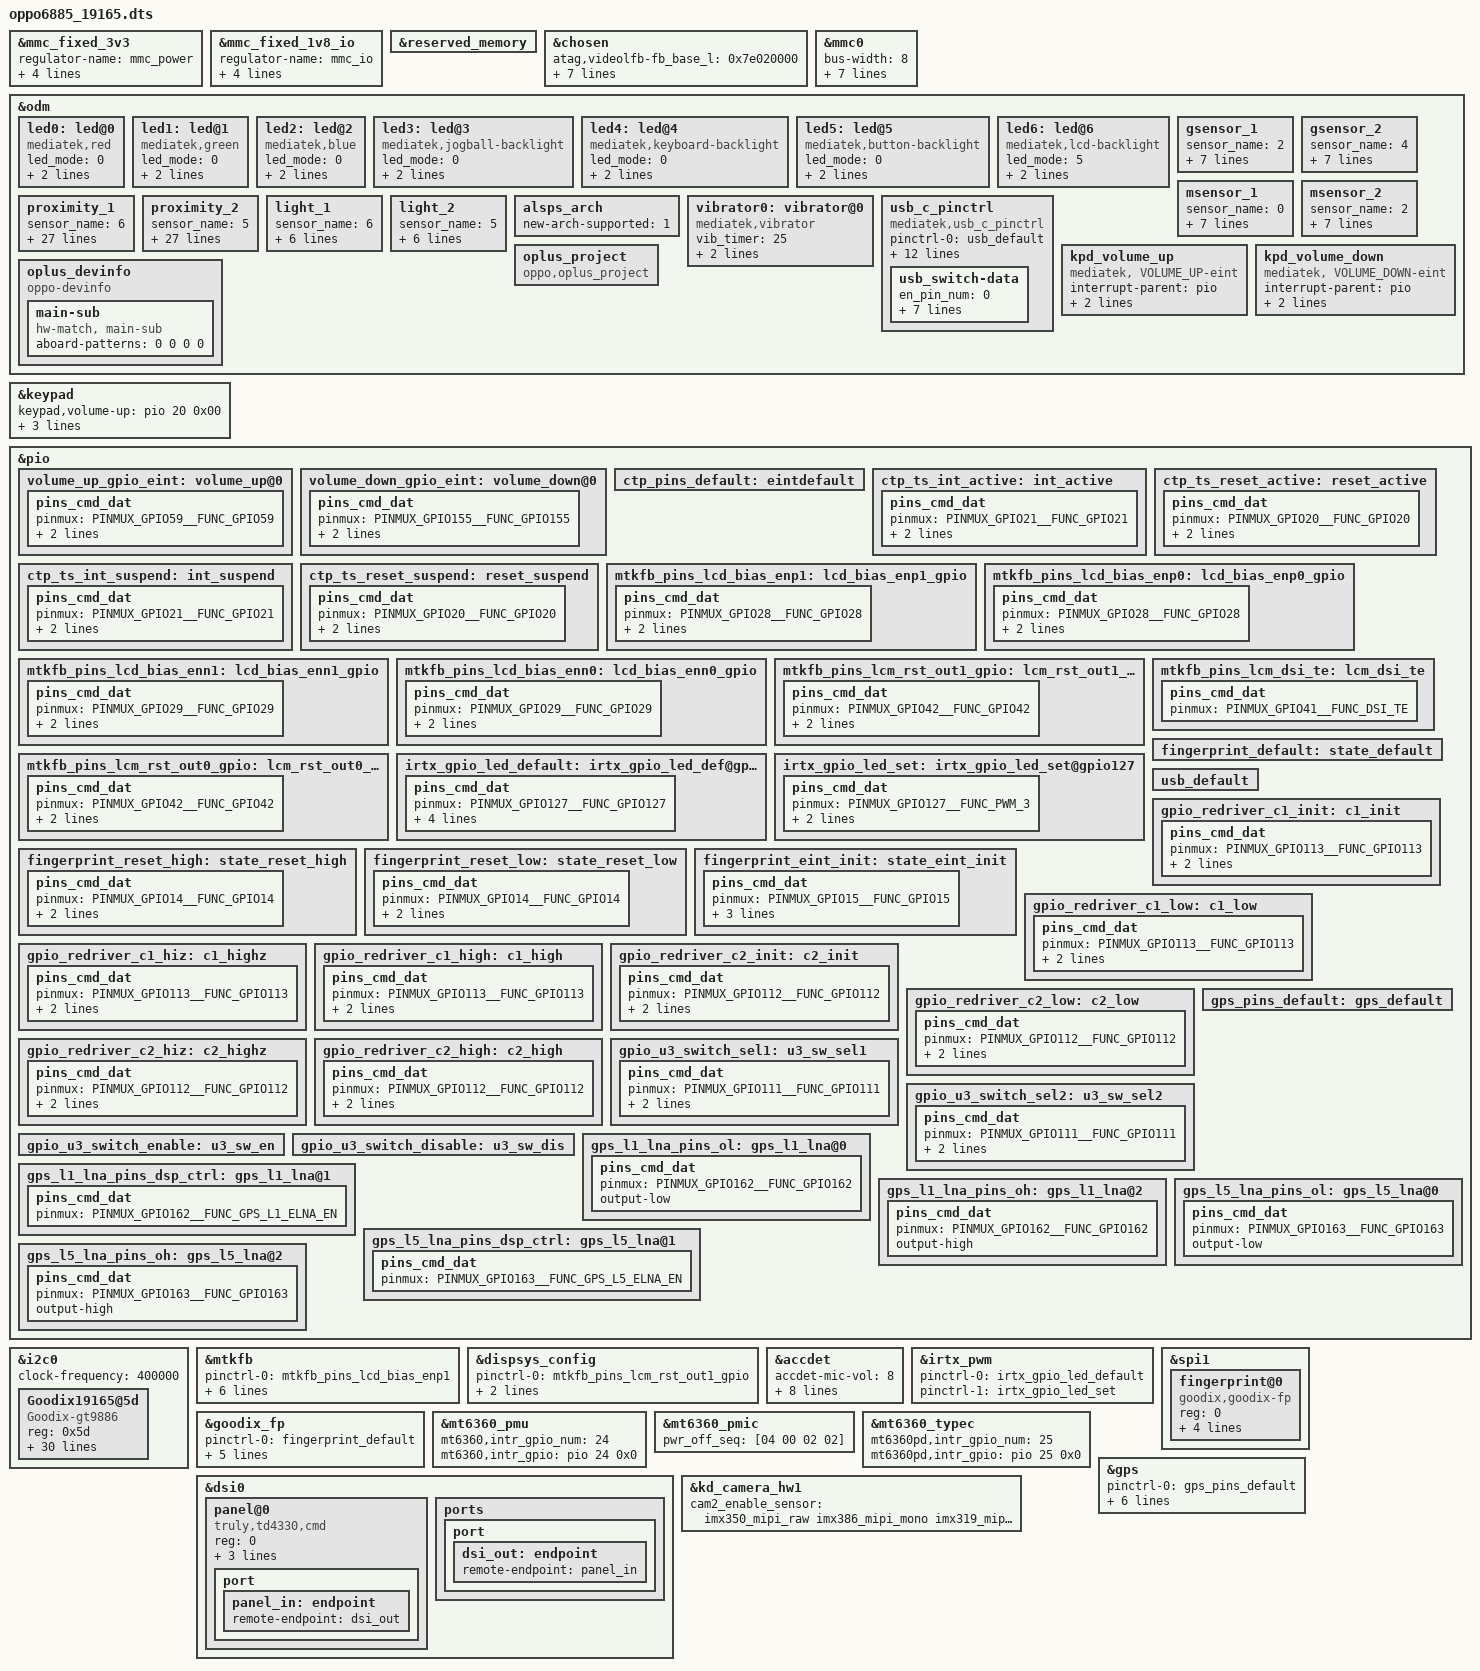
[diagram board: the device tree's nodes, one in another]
/*
 * Mediatek's mt6885 SoC device tree source
 *
 * Copyright (C) 2016 MediaTek Inc.
 *
 * This program is free software; you can redistribute it and/or modify
 * it under the terms of the GNU General Public License version 2 as
 * published by the Free Software Foundation.
 *
 * This program is distributed in the hope that it will be useful,
 * but WITHOUT ANY WARRANTY; without even the implied warranty of
 * MERCHANTABILITY or FITNESS FOR A PARTICULAR PURPOSE.
 * See http://www.gnu.org/licenses/gpl-2.0.html for more details.
 */
/dts-v1/;
/plugin/;
#include <dt-bindings/interrupt-controller/irq.h>
#include <dt-bindings/interrupt-controller/arm-gic.h>
#include <dt-bindings/spmi/spmi.h>
#include <dt-bindings/pinctrl/mt6885-pinfunc.h>

&mmc_fixed_3v3 {
	status = "okay";
	regulator-name = "mmc_power";
	regulator-min-microvolt = <3300000>;
	regulator-max-microvolt = <3300000>;
	enable-active-high;
	regulator-always-on;
};

&mmc_fixed_1v8_io {
	status = "okay";
	regulator-name = "mmc_io";
	regulator-min-microvolt = <1800000>;
	regulator-max-microvolt = <1800000>;
	enable-active-high;
	regulator-always-on;
};

&reserved_memory {
};

/* chosen */
&chosen {

	atag,videolfb-fb_base_l = <0x7e020000>;
	atag,videolfb-fb_base_h = <0x0>;
	atag,videolfb-islcmfound = <1>;
	atag,videolfb-islcm_inited = <0>;
	atag,videolfb-fps= <6000>;
	atag,videolfb-vramSize= <0x1be0000>;
	atag,videolfb-lcmname=
		"nt35595_fhd_dsi_cmd_truly_nt50358_drv";
};

&mmc0 {
	status = "okay";
	/* pinctrl-names = "default", "state_uhs"; */
	/* pinctrl-0 = <&mmc0_pins_default>; */
	/* pinctrl-1 = <&mmc0_pins_uhs>; */
	bus-width = <8>;
	max-frequency = <5000000>;
	cap-mmc-highspeed;
	no-sdio;
	no-sd;
	vmmc-supply = <&mmc_fixed_3v3>;
	vqmmc-supply = <&mmc_fixed_1v8_io>;
	non-removable;
};

&odm {
	led0:led@0 {
		compatible = "mediatek,red";
		led_mode = <0>;
		data = <1>;
		pwm_config = <0 0 0 0 0>;
	};
	led1:led@1 {
		compatible = "mediatek,green";
		led_mode = <0>;
		data = <1>;
		pwm_config = <0 0 0 0 0>;
	};
	led2:led@2 {
		compatible = "mediatek,blue";
		led_mode = <0>;
		data = <1>;
		pwm_config = <0 0 0 0 0>;
	};
	led3:led@3 {
		compatible = "mediatek,jogball-backlight";
		led_mode = <0>;
		data = <1>;
		pwm_config = <0 0 0 0 0>;
	};
	led4:led@4 {
		compatible = "mediatek,keyboard-backlight";
		led_mode = <0>;
		data = <1>;
		pwm_config = <0 0 0 0 0>;
	};
	led5:led@5 {
		compatible = "mediatek,button-backlight";
		led_mode = <0>;
		data = <1>;
		pwm_config = <0 0 0 0 0>;
	};
	led6:led@6 {
		compatible = "mediatek,lcd-backlight";
		led_mode = <5>;
		data = <1>;
		pwm_config = <0 1 0 0 0>;
	};
	/*
	enum {
		LIS3DH,
		LSM6DS3,
		BMI160,
		LIS2HH12,
		LSM6DSM,
		BMI2XY,
	};
	*/
	gsensor_1: gsensor_1 {
		status = "okay";
		sensor_name = <2>;//BMI160
		i2c_num = <2>;
		i2c_addr = <0>;
		direction = <7>;
		eint_num = <3>;
		step_count_7_en = <1>;
		config_miso = <1>;
		correct_y_bias = <1>;
	};

	gsensor_2: gsensor_2 {
		status = "okay";
		sensor_name = <4>;//LSM6DSM
		i2c_num = <2>;
		i2c_addr = <0>;
		direction = <5>;
		eint_num = <3>;
		step_count_7_en = <1>;
		config_miso = <1>;
		correct_y_bias = <1>;
	};
	/*
	enum {
		AKM09911,
		MMC3530,
		MMC5603,
		MXG4300,
	};
	*/
	msensor_1: msensor_1 {
		status = "okay";
		sensor_name = <0>;//AKM09911
		i2c_num = <0>;
		i2c_addr = <12>;
		direction = <4>;
		eint_num = <0>;
		parameter-number= <18>;
		soft-mag-parameter = <9263 1 322 0 140 0 48 1 10701 1 125 0 103 1 140 1 10726 1>; // not using
	};
	msensor_2: msensor_2 {
		status = "okay";
		sensor_name = <2>;//MMC5603
		i2c_num = <0>;
		i2c_addr = <48>;
		direction = <7>;
		eint_num = <0>;
		parameter-number= <18>;
		soft-mag-parameter = <9991 0 412 0 85 1 122 1 10184 0 328 1 186 1 14 0 10516 0>;
	};
	/*
	enum {
		TMD2725,
		APSD9922,
		STK3335,
		STK3331,
		STK2232,
		TCS3701,
		STK32600,
	};
	*/
	proximity_1: proximity_1 {
		status = "okay";
		sensor_name = <6>;//STK32600
		i2c_num = <0>;
		i2c_addr = <72>;
		direction = <4>;
		eint_num = <11>;
		low_step = <300>;
		high_step = <400>;
		low_limit = <650>;
		high_limit = <1050>;
		dirty_low_step = <300>;
		dirty_high_step = <400>;
		ps_dirty_limit = <1800>;
		ps_ir_limit = <2000>;
		ps_adjust_min = <0>;
		ps_adjust_max = <1850>;
		sampling_count = <5>;
		step_max = <400>;
		step_min = <100>;
		step_div = <2000>;
		anti_shake_delta = <70>;
		dynamic_cali_max = <2000>;
		raw2offset_radio = <1000>;
		offset_max = <60000>;
		offset_range_min = <0>;
		offset_range_max = <65534>;
		force_cali_limit = <2000>;
		cali_jitter_limit = <20>;
		cal_offset_margin = <3000>;
	};
	proximity_2: proximity_2 {
		status = "okay";
		sensor_name = <5>;//TCS3701
		i2c_num = <0>;
		i2c_addr = <57>;
		direction = <4>;
		eint_num = <11>;
		low_step = <300>;
		high_step = <400>;
		low_limit = <400>;
		high_limit = <600>;
		dirty_low_step = <180>;
		dirty_high_step = <250>;
		ps_dirty_limit = <1023>;
		ps_ir_limit = <500>;
		ps_adjust_min = <0>;
		ps_adjust_max = <600>;
		sampling_count = <5>;
		step_max = <400>;
		step_min = <110>;
		step_div = <1500>;
		anti_shake_delta = <80>;
		dynamic_cali_max = <1024>;
		raw2offset_radio = <20800>;
		offset_max = <250>;
		offset_range_min = <255>;
		offset_range_max = <255>;
		force_cali_limit = <2000>;
		cali_jitter_limit = <30>;
		cal_offset_margin = <120>;
	};
	light_1: light_1 {
		status = "okay";
		sensor_name = <6>;//STK32600
		i2c_num = <0>;
		i2c_addr = <72>;
		direction = <4>;
		eint_num = <11>;
		als_buffer_length =<8>;
		als_ratio = <65>;
	};
	light_2: light_2 {
		status = "okay";
		sensor_name = <5>;//TCS3701
		i2c_num = <0>;
		i2c_addr = <57>;
		direction = <4>;
		eint_num = <11>;
		als_buffer_length = <10>;
		als_ratio = <110>;
	};
	alsps_arch: alsps_arch {
		status = "okay";
		new-arch-supported = <1>;
	};
	vibrator0:vibrator@0 {
		compatible = "mediatek,vibrator";
		vib_timer = <25>;
		vib_limit = <9>;
		vib_vol= <9>;
	};
	usb_c_pinctrl:usb_c_pinctrl {
		compatible = "mediatek,usb_c_pinctrl";
	};

/*VENDOR_EDIT keypad start*/
	kpd_volume_up:kpd_volume_up {
		compatible = "mediatek, VOLUME_UP-eint";
		interrupt-parent = <&pio>;
		interrupts = <59 IRQ_TYPE_EDGE_FALLING 59 0>;
		debounce = <32000>;
		status = "okay";
	};

	kpd_volume_down:kpd_volume_down {
		compatible = "mediatek, VOLUME_DOWN-eint";
		interrupt-parent = <&pio>;
		interrupts = <155 IRQ_TYPE_EDGE_FALLING 155 0>;
		debounce = <32000>;
		status = "okay";
	};
/*VENDOR_EDIT keypad end*/

	oplus_project:oplus_project {
		compatible = "oppo,oplus_project";
	};
	oplus_devinfo:oplus_devinfo {
		compatible = "oppo-devinfo";

		main-sub {
			compatible = "hw-match, main-sub";
			aboard-patterns = <0 0 0 0>;
			/*main board*/
			//match-projects = <19537 19538 19541 19539>;
		};
	};
};
/*VENDOR_EDIT*/
&keypad {
	keypad,volume-up	= <&pio 20 0x00>;
	keypad,volume-down	= <&pio 155 0x00>;
	pinctrl-names = "volume_up_as_int", "volume_down_as_int";
	pinctrl-0 = <&volume_up_gpio_eint>;
	pinctrl-1 = <&volume_down_gpio_eint>;
	status = "okay";
};

&pio {
	volume_up_gpio_eint:volume_up@0{
		pins_cmd_dat {
			pinmux = <PINMUX_GPIO59__FUNC_GPIO59>;
			slew-rate = <0>;  /*direction 0:in, 1:out*/
			input-enable;
		};
	};

	volume_down_gpio_eint:volume_down@0{
		pins_cmd_dat {
			pinmux = <PINMUX_GPIO155__FUNC_GPIO155>;
			slew-rate = <0>;  /*direction 0:in, 1:out*/
			input-enable;
		};
	};
};
/*VENDOR_EDIT*/
&i2c0 {
	clock-frequency = <400000>;
	status = "okay";
	Goodix19165@5d {
		compatible = "Goodix-gt9886";
		reg = <0x5d>;
		chip-name = "GT9886";

		/* Interrupt && Irq-gpio */
		interrupt-parent = <&pio>;
		interrupts = <21 IRQ_TYPE_EDGE_FALLING 21 0>;

		/* Power Config */
		vdd_2v8-supply = <&mt_pmic_vtp_ldo_reg>;
		vdd_2v8_volt = <2950000>;

		/* Other HW Resource */
		irq-gpio = <&pio 21 0x2002>;
		reset-gpio = <&pio 20 0>;
		pinctrl-names = "default";

		vid_len = <0>;
		tp_type = <8>;
		// type of tp_dev ,TP-SAMSUNG = 8;
		platform_support_project = <19165 19166>;
		platform_support_project_dir = <19165 19165>;
		platform_support_project_commandline = "s68fc01", "s68fc01";

		touchpanel,max-num-support = <10>;
		touchpanel,tx-rx-num = <15 34>;
		touchpanel,panel-coords = <1080 2400>;
		touchpanel,display-coords = <1080 2400>;
		touchpanel,touchmajor-limit = <0 54>;

		/* SW Support Feature Control */
		register-is-16bit;
		black_gesture_support;
		fw_edge_limit_support;
		pressure_report_support;
		//spurious_fingerprint_support;
		charger_pump_support;
		game_switch_support;
		//face_detect_support;
		smart_gesture_support;
		fw_update_app_support;
		fingerprint_underscreen_support;
		esd_handle_support;
		/*
		 *Virtual Key Config:
		 *1:touchpanel,button-type: <virtualkey_type  supportted_button-map>
		 *virtualkey_type:
		 *Type 1: using board_properties
		 *Type 2: using same IC (button zone&& touch zone are seprate)
		 *Type 3: using diffrent IC (button zone&& touch zone are seprate)
		 *Type 4: No need of virtual key process
		 *supportted_button-map:select|menu|home|back
		 *
		 *2:touchpanel,button-map
		 *type (X1,Y1)(X2,Y2)(X3,Y3)(Width_X,Hight_Y)--Only when button-type is 0
		 */
		touchpanel,button-type = <4>;
		touchpanel.button-TRx = <0 0>;
	};

};
&pio {
	ctp_pins_default: eintdefault {
	};
	ctp_ts_int_active: int_active {
		pins_cmd_dat {
			pinmux = <PINMUX_GPIO21__FUNC_GPIO21>;
			slew-rate = <0>;
			bias-pull-up = <11>;
		};
	};
	ctp_ts_reset_active: reset_active {
		pins_cmd_dat {
			pinmux = <PINMUX_GPIO20__FUNC_GPIO20>;
			slew-rate = <1>;
			output-high;
		};
	};
	ctp_ts_int_suspend: int_suspend {
		pins_cmd_dat {
			pinmux = <PINMUX_GPIO21__FUNC_GPIO21>;
			slew-rate = <1>;
			output-low;
		};
	};
	ctp_ts_reset_suspend: reset_suspend {
		pins_cmd_dat {
			pinmux = <PINMUX_GPIO20__FUNC_GPIO20>;
			slew-rate = <1>;
			output-low;
		};
	};
};
/* TOUCH end */

/* DISPSYS GPIO standardization */
&pio {
	mtkfb_pins_lcd_bias_enp1: lcd_bias_enp1_gpio {
		pins_cmd_dat {
			pinmux = <PINMUX_GPIO28__FUNC_GPIO28>;
			slew-rate = <1>;
			output-high;
		};
	};

	mtkfb_pins_lcd_bias_enp0: lcd_bias_enp0_gpio {
		pins_cmd_dat {
			pinmux = <PINMUX_GPIO28__FUNC_GPIO28>;
			slew-rate = <1>;
			output-low;
		};
	};

	mtkfb_pins_lcd_bias_enn1: lcd_bias_enn1_gpio {
		pins_cmd_dat {
			pinmux = <PINMUX_GPIO29__FUNC_GPIO29>;
			slew-rate = <1>;
			output-high;
		};
	};

	mtkfb_pins_lcd_bias_enn0: lcd_bias_enn0_gpio {
		pins_cmd_dat {
			pinmux = <PINMUX_GPIO29__FUNC_GPIO29>;
			slew-rate = <1>;
			output-low;
		};
	};

	mtkfb_pins_lcm_rst_out1_gpio: lcm_rst_out1_gpio {
		pins_cmd_dat {
			pinmux = <PINMUX_GPIO42__FUNC_GPIO42>;
			slew-rate = <1>;
			output-high;
		};
	};

	mtkfb_pins_lcm_rst_out0_gpio: lcm_rst_out0_gpio {
		pins_cmd_dat {
			pinmux = <PINMUX_GPIO42__FUNC_GPIO42>;
			slew-rate = <1>;
			output-low;
		};
	};

	mtkfb_pins_lcm_dsi_te: lcm_dsi_te {
		pins_cmd_dat {
			pinmux = <PINMUX_GPIO41__FUNC_DSI_TE>;
		};
	};
};

&mtkfb {
	pinctrl-names = "lcd_bias_enp1_gpio", "lcd_bias_enp0_gpio",
		"lcd_bias_enn1_gpio", "lcd_bias_enn0_gpio",
		"lcm_rst_out1_gpio", "lcm_rst_out0_gpio",
		"mode_te_te";
	pinctrl-0 = <&mtkfb_pins_lcd_bias_enp1>;
	pinctrl-1 = <&mtkfb_pins_lcd_bias_enp0>;
	pinctrl-2 = <&mtkfb_pins_lcd_bias_enn1>;
	pinctrl-3 = <&mtkfb_pins_lcd_bias_enn0>;
	pinctrl-4 = <&mtkfb_pins_lcm_rst_out1_gpio>;
	pinctrl-5 = <&mtkfb_pins_lcm_rst_out0_gpio>;
	pinctrl-6 = <&mtkfb_pins_lcm_dsi_te>;
	status = "okay";
};

&dispsys_config {
	pinctrl-names =
		"lcm_rst_out1_gpio", "lcm_rst_out0_gpio",
		"mode_te_te";
	pinctrl-0 = <&mtkfb_pins_lcm_rst_out1_gpio>;
	pinctrl-1 = <&mtkfb_pins_lcm_rst_out0_gpio>;
	pinctrl-2 = <&mtkfb_pins_lcm_dsi_te>;
	status = "okay";
};
/* DISPSYS GPIO standardization end */

/* accdet start */
&accdet {
	/* accdet micbias voltage: 0x09:2.85v 0x08:2.8v 0x07,
	 * 2.7v;0x05,2.5v;0x02,1.9v
	 */
	accdet-mic-vol = <8>;
	/* accdet pwm_width, pwm_thresh, fall_delay, rise_delay
	 * debounce0, debounce1, debounce3, debounce4
	 * eint pwm_width, eint pwm_thresh
	 * eint deb(debounce0, debounce1, debounce2, debounce3), inv_debounce
	 */
	headset-mode-setting = <0x500 0x500 1 0x1f0
				0x800 0x800 0x20 0x44
				0x4 0x1
				0x5 0x3 0x3 0x5 0xe>;
	accdet-plugout-debounce = <1>;
	/*1:ACC mode, 2:low cost without in bias, 6:low cost with in bias*/
	accdet-mic-mode = <2>;
	/*0--MD_MAX--UP_MAX--DW_MAX*/
	headset-three-key-threshold = <0 80 220 400>;
	headset-three-key-threshold-CDD = <0 121 192 600>;
	/*0--MD_MAX--VOICE_MAX--UP_MAX--DW_MAX*/
	headset-four-key-threshold = <0 58 121 192 400>;

	/* select VTH to 2v and 500k, use internal resitance */
	eint_use_ext_res = <0>;
	status = "okay";
};
/* accdet end */

/* IRTX GPIO Start */
&irtx_pwm {
	pinctrl-names = "irtx_gpio_led_default", "irtx_gpio_led_set";
	pinctrl-0 = <&irtx_gpio_led_default>;
	pinctrl-1 = <&irtx_gpio_led_set>;
	status = "okay";
};
&pio {
	/* IRTX GPIO Settings -Start */
	/* default: GPIO0, output, high */
	irtx_gpio_led_default:irtx_gpio_led_def@gpio127 {
		pins_cmd_dat {
			pinmux = <PINMUX_GPIO127__FUNC_GPIO127>;
			slew-rate = <1>;
			bias-disable;
			output-low;
			input-schmitt-enable = <0>;
		};
	};

	irtx_gpio_led_set:irtx_gpio_led_set@gpio127 {
		pins_cmd_dat {
			pinmux = <PINMUX_GPIO127__FUNC_PWM_3>;
			slew-rate = <1>;
			output-high;
		};
	};
}; /* IRTX GPIO Settings -End */

/* FINGERPRINT start */
&spi1 {
	#address-cells = <1>;
	#size-cells = <0>;
	fingerprint@0 {
		compatible = "goodix,goodix-fp";
		reg = <0>;
		spi-max-frequency = <8000000>;
		netlink-event = <30>;
		vfp-supply = <&mt_pmic_vfp_ldo_reg>;
		power-type = <1>;
		status = "okay";
	};
};

&goodix_fp {
	pinctrl-names = "default", "reset_high", "reset_low", "eint_init";
	pinctrl-0 = <&fingerprint_default>;
	pinctrl-1 = <&fingerprint_reset_high>;
	pinctrl-2 = <&fingerprint_reset_low>;
	pinctrl-3 = <&fingerprint_eint_init>;
	interrupt-parent = <&pio>;
	interrupts = <15 IRQ_TYPE_EDGE_RISING 15 0>;
	status = "okay";
};

&pio {
	fingerprint_default: state_default {
	};
	fingerprint_reset_high: state_reset_high {
		pins_cmd_dat {
			pinmux = <PINMUX_GPIO14__FUNC_GPIO14>;
			slew-rate = <1>;
			output-high;
		};
	};
	fingerprint_reset_low: state_reset_low {
		pins_cmd_dat {
			pinmux = <PINMUX_GPIO14__FUNC_GPIO14>;
			slew-rate = <1>;
			output-low;
		};
	};
	fingerprint_eint_init: state_eint_init {
		pins_cmd_dat {
			pinmux = <PINMUX_GPIO15__FUNC_GPIO15>;
			slew-rate = <0>;
			bias-pull-up = <MTK_PUPD_SET_R1R0_10>;
			input-schmitt-enable;
		};
	};
};
/* FINGERPRINT end */

&mt6360_pmu {
	mt6360,intr_gpio_num = <24>; /* direct defined GPIO num */
	mt6360,intr_gpio = <&pio 24 0x0>;
};

&mt6360_pmic {
	pwr_off_seq = [04 00 02 02];
};

&mt6360_typec {
	mt6360pd,intr_gpio_num = <25>; /* direct defined GPIO num */
	mt6360pd,intr_gpio = <&pio 25 0x0>;
};

/* USB SWITCH GPIO start */
&pio {
	usb_default: usb_default {
	};

	gpio_redriver_c1_init: c1_init {
		pins_cmd_dat {
			pinmux = <PINMUX_GPIO113__FUNC_GPIO113>;
			slew-rate = <1>;
			output-low;
		};
	};

	gpio_redriver_c1_low: c1_low {
		pins_cmd_dat {
			pinmux = <PINMUX_GPIO113__FUNC_GPIO113>;
			slew-rate = <1>;
			output-low;
		};
	};

	gpio_redriver_c1_hiz: c1_highz {
		pins_cmd_dat {
			pinmux = <PINMUX_GPIO113__FUNC_GPIO113>;
			slew-rate= <0>;
			bias-disable;
		};
	};

	gpio_redriver_c1_high: c1_high {
		pins_cmd_dat {
			pinmux = <PINMUX_GPIO113__FUNC_GPIO113>;
			slew-rate = <1>;
			output-high;
		};
	};

	gpio_redriver_c2_init: c2_init {
		pins_cmd_dat {
			pinmux = <PINMUX_GPIO112__FUNC_GPIO112>;
			slew-rate = <1>;
			output-low;
		};
	};

	gpio_redriver_c2_low: c2_low {
		pins_cmd_dat {
			pinmux = <PINMUX_GPIO112__FUNC_GPIO112>;
			slew-rate = <1>;
			output-low;
		};
	};

	gpio_redriver_c2_hiz: c2_highz {
		pins_cmd_dat {
			pinmux = <PINMUX_GPIO112__FUNC_GPIO112>;
			slew-rate= <0>;
			bias-disable;
		};
	};

	gpio_redriver_c2_high: c2_high {
		pins_cmd_dat {
			pinmux = <PINMUX_GPIO112__FUNC_GPIO112>;
			slew-rate = <1>;
			output-high;
		};
	};

	gpio_u3_switch_sel1: u3_sw_sel1 {
		pins_cmd_dat {
			pinmux = <PINMUX_GPIO111__FUNC_GPIO111>;
			slew-rate = <1>;
			output-low;
		};
	};

	gpio_u3_switch_sel2: u3_sw_sel2 {
		pins_cmd_dat {
			pinmux = <PINMUX_GPIO111__FUNC_GPIO111>;
			slew-rate = <1>;
			output-high;
		};
	};

	gpio_u3_switch_enable: u3_sw_en {
	};

	gpio_u3_switch_disable: u3_sw_dis {
	};
};

&usb_c_pinctrl {
	pinctrl-names = "usb_default",
		"redrv_c1_init",
		"redrv_c1_low",
		"redrv_c1_hiz",
		"redrv_c1_high",
		"redrv_c2_init",
		"redrv_c2_low",
		"redrv_c2_hiz",
		"redrv_c2_high",
		"switch_sel1",
		"switch_sel2",
		"switch_enable",
		"switch_disable";

	pinctrl-0 = <&usb_default>;
	pinctrl-1 = <&gpio_redriver_c1_init>;
	pinctrl-2 = <&gpio_redriver_c1_low>;
	pinctrl-3 = <&gpio_redriver_c1_hiz>;
	pinctrl-4 = <&gpio_redriver_c1_high>;
	pinctrl-5 = <&gpio_redriver_c2_init>;
	pinctrl-6 = <&gpio_redriver_c2_low>;
	pinctrl-7 = <&gpio_redriver_c2_hiz>;
	pinctrl-8 = <&gpio_redriver_c2_high>;
	pinctrl-9 = <&gpio_u3_switch_sel1>;
	pinctrl-10 = <&gpio_u3_switch_sel2>;
	pinctrl-11 = <&gpio_u3_switch_enable>;
	pinctrl-12 = <&gpio_u3_switch_disable>;
	status = "okay";

	usb_switch-data {
		en_pin_num = <0>;
		en_pin_val = <0>;
		sel_pin_num = <111>;
		sel_pin_val = <1>;
		c1_pin_num = <113>;
		c1_pin_val = <2>;
		c2_pin_num = <112>;
		c2_pin_val = <1>;
	};
};
/* USB SWITCH GPIO end */

/* GPS GPIO standardization start */
&pio {
	gps_pins_default: gps_default {
	};

	gps_l1_lna_pins_ol: gps_l1_lna@0 {
		pins_cmd_dat {
			pinmux = <PINMUX_GPIO162__FUNC_GPIO162>;
			output-low;
		};
	};
	gps_l1_lna_pins_dsp_ctrl: gps_l1_lna@1 {
		pins_cmd_dat {
			pinmux = <PINMUX_GPIO162__FUNC_GPS_L1_ELNA_EN>;
		};
	};
	gps_l1_lna_pins_oh: gps_l1_lna@2 {
		pins_cmd_dat {
			pinmux = <PINMUX_GPIO162__FUNC_GPIO162>;
			output-high;
		};
	};

	gps_l5_lna_pins_ol: gps_l5_lna@0 {
		pins_cmd_dat {
			pinmux = <PINMUX_GPIO163__FUNC_GPIO163>;
			output-low;
		};
	};
	gps_l5_lna_pins_dsp_ctrl: gps_l5_lna@1 {
		pins_cmd_dat {
			pinmux = <PINMUX_GPIO163__FUNC_GPS_L5_ELNA_EN>;
		};
	};
	gps_l5_lna_pins_oh: gps_l5_lna@2 {
		pins_cmd_dat {
			pinmux = <PINMUX_GPIO163__FUNC_GPIO163>;
			output-high;
		};
	};
};

&gps {
	pinctrl-names = "default",
		"gps_l1_lna_disable",
		"gps_l1_lna_dsp_ctrl",
		"gps_l1_lna_enable",
		"gps_l5_lna_disable",
		"gps_l5_lna_dsp_ctrl",
		"gps_l5_lna_enable";
	pinctrl-0 = <&gps_pins_default>;
	pinctrl-1 = <&gps_l1_lna_pins_ol>;
	pinctrl-2 = <&gps_l1_lna_pins_dsp_ctrl>;
	pinctrl-3 = <&gps_l1_lna_pins_oh>;
	pinctrl-4 = <&gps_l5_lna_pins_ol>;
	pinctrl-5 = <&gps_l5_lna_pins_dsp_ctrl>;
	pinctrl-6 = <&gps_l5_lna_pins_oh>;
	status = "okay";
};
/* GPS GPIO standardization end */

&dsi0 {
	status = "okay";
	#address-cells = <1>;
	#size-cells = <0>;
	panel@0 {
		compatible = "truly,td4330,cmd";
		reg = <0>;
		pm-enable-gpios = <&pio 41 0>;
		reset-gpios = <&pio 42 0>;
		bias-gpios = <&pio 28 0>,
			<&pio 29 0>;
		pinctrl-names = "default";
		port {
			panel_in: endpoint {
				remote-endpoint = <&dsi_out>;
			};
		};
	};
	ports {
		port {
			dsi_out: endpoint {
				remote-endpoint = <&panel_in>;
			};
		};
	};
};

/* CAMERA specify sensor */
&kd_camera_hw1 {
	cam2_enable_sensor = "imx350_mipi_raw imx386_mipi_mono imx319_mipi_raw";
};
/* CAMERA specify sensor end */

//#include "mediatek/cust_mt6885_touch_1080x2280.dtsi"
#include "mediatek/cust_mt6885_camera.dtsi"
#include <oppo6885_19165/cust.dtsi>
/*End of this file, DO NOT ADD ANYTHING HERE*/
